# K32W061 register map
Vendor: nxp.com; File version: 1.0
CPU: CM4 r0p1, little endian, MPU, no FPU, VTOR, 3 interrupt priority bits
Registers are 32-bit, read-write, reset 0x0 unless marked. A register's access mark holds for its fields unless they carry their own. Offsets are from the block's base; [hi:lo] are bit positions; {n}, {i} and the like mark numbered series.

## I2C0 — This is the description of component i2c It is an Inter IC with APB bus interface. More details will follow.
Base 0x40003000; alternate view of FLEXCOMM2
Same registers: I2C1 0x40004000 (alternate view of FLEXCOMM3), I2C2 0x40005000 (alternate view of FLEXCOMM6)
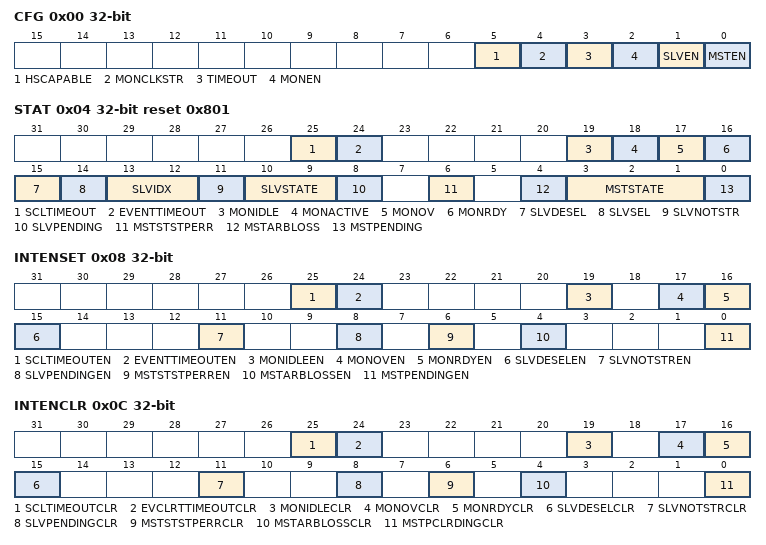
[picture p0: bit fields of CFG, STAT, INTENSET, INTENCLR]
0x00 CFG — Configuration for shared functions.
  [5] HSCAPABLE — High-speed mode Capable enable. Since High Speed mode alters the way I2C pins drive and filter, as well as the timing for certain I2C signalling, enabling High-speed mode applies to all functions: master, slave, and monitor.
  [4] MONCLKSTR — Monitor function Clock Stretching.
  [3] TIMEOUT — I2C bus Time-out Enable. When disabled, the time-out function is internally reset.
  [2] MONEN — Monitor Enable. When disabled, configurations settings for the Monitor function are not changed, but the Monitor function is internally reset.
  [1] SLVEN — Slave Enable. When disabled, configurations settings for the Slave function are not changed, but the Slave function is internally reset.
  [0] MSTEN — Master Enable. When disabled, configurations settings for the Master function are not changed, but the Master function is internally reset.
0x04 STAT reset 0x801 — Status register for Master, Slave and Monitor functions.
  [25] SCLTIMEOUT — SCL Time-out Interrupt flag. Indicates when SCL has remained low longer than the time specific by the TIMEOUT register. The flag is cleared by writing a 1 to this bit. 0: No time-out. SCL low time has not caused a time-out. 1: Time-out. SCL low time has not caused a time-out.
  [24] EVENTTIMEOUT — Event Time-out Interrupt flag. Indicates when the time between events has been longer than the time specified by the TIMEOUT register. Events include Start, Stop, and clock edges. The flag is cleared by writing a 1 to this bit. No time-out is created when the I2C-bus is idle. 0: No time-out. I2C bus events have not casued a time-out. 1: Event time-out. The time between I2C bus events has been longer than the time specified by the TIMEOUT register.
  [19] MONIDLE — Monitor Idle flag. This flag is set when the Monitor function sees the I2C bus change from active to inactive. This can be used by software to decide when to process data accumulated by the Monitor function. This flag will cause an interrupt when set if enabled via the INTENSET register. The flag can be cleared by writing a 1 to this bit. 0: Not idle. The I2C bus is not idle, or this flag has been cleared by software. 1: Idle. The I2C bus has gone idle at least once since the last time this flag was cleared by software.
  [18] MONACTIVE ro — Monitor Active flag. Indicates when the Monitor function considers the I2C bus to be active. Active is defined here as when some Master is on the bus: a bus Start has occurred more recently than a bus Stop. 0: Inactive. The Monitor function considers the I2C bus to be inactive. 1: Active. The Monitor function considers the I2C bus to be active.
  [17] MONOV — Monitor Overflow flag. 0: No overrun. Monitor data has not overrun 1: Overrun. A monitor data overrun has occurred. This can only happen when Monitor clock stretching is not enabled via the MOCCLKSTR bit in the CFG register. Writing 1 to this bit clears the flag.
  [16] MONRDY ro — Monitor Ready. This flag is cleared when the MONRXDAT register is read. 0: No data. The Monitor function does not currently have data available. 1: Data waiting. The Monitor function has data waiting to be read.
  [15] SLVDESEL — Slave Deselected flag. This flag will cause an interrupt when set if enabled via INTENSET. This flag can be cleared by writing a 1 to this bit. 0: Not deselected. The slave function has not become deslected. This does not mean that it is currently selected. That information can be found in the SLVSEL flag. 1: Deselected. The slave function has become deselected. This is specifically caused by the SLVSEL flag changing from 1 to 0. See the description of SLVSEL for details on when that event occurs.
  [14] SLVSEL — Slave selected flag. SLVSEL is set after an address match when software tells the Slave function to acknowledge the address, or when the address has been automatically acknowledged. It is cleared when another address cycle presents an address that does not match an enabled address on the Slave function, when slave software decides to NACK a matched address, when there is a Stop detected on the bus, when the master NACKs slave data, and in some combinations of Automatic Operation. SLVSEL is not cleared if software NACKs data. 0: Not selected. The slave function is not currently selected. 1: Selected. The slave function is currently selected.
  [13:12] SLVIDX ro — Slave address match Index. This field is valid when the I2C slave function has been selected by receiving an address that matches one of the slave addresses defined by any enabled slave address registers, and provides an identification of the address that was matched. It is possible that more than one address could be matched, but only one match can be reported here. 0: Address 0. Slave address 0 was matched. 1: Address 1. Slave address 1 was matched. 2: Address 2. Slave address 2 was matched. 3: Address 3. Slave address 3 was matched.
  [11] SLVNOTSTR ro — Slave Not Stretching. Indicates when the slave function is stretching the I2C clock. This is needed in order to gracefully invoke Deep Sleep or Power-down modes during slave operation. This read-only flag reflects the slave function status in real time. 0: stretching. The slave function is currently stretching the I2C bus clock. Deep-sleep mode can not be entered at this time. 1. Not stretching. The slave function is not currently stretching the I2C bus clock. Deep-sleep mode could be entered at this time.
  [10:9] SLVSTATE ro — Slave State code. Each value of this field indicates a specific required service for the Slave function. All other values are reserved. See Table 393 for state values and actions. Remark: note that the occurrence of some states and how they are handled are affected by DMA mode and Automatic Operation modes. Slave state codes are: 0: Slave address. Address plus R/W received. At least one of the four slave addresses has been matched by hardware. 1: Slave receive. Received data is available (Slave Receiver mode). 2: Slave transmit. Data can be transmitted (Slave transmitter mode).
  [8] SLVPENDING ro — Slave Pending. Indicates that the Slave function is waiting to continue communication on the I2C-bus and needs software service. This flag will cause an interrupt when set if enabled via INTENSET. The SLVPENDING flag is not set when the DMA is handling an event (if the SLVDMA bit in the SLVCTL register is set). The SLVPENDING flag is read-only and is automatically cleared when a 1 is written to the SLVCONTINUE bit in the SLVCTL register. The point in time when SlvPending is set depends on whether the I2C interface is in HSCAPABLE mode. When the I2C interface is configured to be HSCAPABLE, HS master codes are detected automatically. Due to the requirements of the HS I2C specification, slave addresses must also be detected automatically, since the address must be acknowledged before the clock can be stretched. 0: In progress. The slave function does not currently need service. 1: Pending. The Slave function needs service. Information on what is needed can be found in the adjacent SLVSTATE field.
  [6] MSTSTSTPERR — Master Start/Stop Error flag. This flag can be cleared by software writing a 1 to this bit. It is also cleared automatically a 1 is written to MSTCONTINUE. 0: No start/stop Error has occurred. 1: The master function has experienced a Start/Stop Error. A Start or Stop was detected at a time when it is not allowed by the I2C specification. The Master interface has stopped driving the bus and gone to an idle state, no action is required. A request for a Start could be made, or software could attempt to insure that thet bus has not stalled.
  [4] MSTARBLOSS — Master Arbitration Loss flag. This flag can be cleared by software writing a 1 to this bit. It is also cleared automatically a 1 is written to MSTCONTINUE. 0: No Arbitration Loss has occurred. 1: Arbitration Loss. The mater function has experienced an Arbitration Loss. At this point, the Master function has already stopped driving the bus and gone to an idle state. Software can respond by doing nothing, or by sending a Start in order to attempt to gain control of the bus when it next becomes idle.
  [3:1] MSTSTATE ro — Master State code. The master state code reflects the master state when the MSTPENDING bit is set, that is the master is pending or in the idle state. Each value of this field indicates a specific required service for the Master function. All other values are reserved. 0: Idle. The Master function is available to be used for a new transaction. 1: Receive ready. Received data available (Master Receiver mode). Address plus Read was previously sent and Acknowledged by slave. 2: Transmit ready. Data can be transmitted (Master Transmitter mode). Address plus Write was previously sent and Acknowledged by slave. 3: NACK address. Slave NACKed address. 4: NACK data. Slave NACKed transmitted data.
  [0] MSTPENDING ro — Master Pending. Indicates that the Master is waiting to continue communication on the I2C-bus (pending) or is idle. When the master is pending, the MSTSTATE bits indicate what type of software service if any the master expects. This flag will cause an interrupt when set if, enabled via the INTENSET register. The MSTPENDING flag is not set when the DMA is handling an event (if the MSTDMA bit in the MSTCTL register is set). If the master is in the idle state, and no communication is needed, mask this interrupt. 0: In progress. Communication is in progress and the Master function is busy and cannot currently accept a command. 1: Pending. The Master function needs software service or is in the idle state. If the master is not in the idle state, it is waiting to receive or transmit data or the NACK bit.
0x08 INTENSET — Interrupt Enable Set and read register.
  [25] SCLTIMEOUTEN — SCL time-out interrupt Enable. 0: interrupt is disabled. 1: interrupt is enabled.
  [24] EVENTTIMEOUTEN — Event time-out interrupt Enable. 0: interrupt is disabled. 1: interrupt is enabled.
  [19] MONIDLEEN — Monitor Idle interrupt Enable. 0: interrupt is disabled. 1: interrupt is enabled.
  [17] MONOVEN — Monitor Overrun interrupt Enable. 0: interrupt is disabled. 1: interrupt is enabled.
  [16] MONRDYEN — Monitor data Ready interrupt Enable. 0: interrupt is disabled. 1: interrupt is enabled.
  [15] SLVDESELEN — Slave Deselect interrupt Enable. 0: interrupt is disabled. 1: interrupt is enabled.
  [11] SLVNOTSTREN — Slave Not Stretching interrupt Enable. 0: interrupt is disabled. 1: interrupt is enabled.
  [8] SLVPENDINGEN — Slave Pending interrupt Enable. 0: interrupt is disabled. 1: interrupt is enabled.
  [6] MSTSTSTPERREN — Master Start/Stop Error interrupt Enable. 0: interrupt is disabled. 1: interrupt is enabled.
  [4] MSTARBLOSSEN — Master Arbitration Loss interrupt Enable. 0: interrupt is disabled. 1: interrupt is enabled.
  [0] MSTPENDINGEN — Master Pending interrupt Enable. 0: interrupt is disabled. 1: interrupt is enabled.
0x0C INTENCLR reset not defined — Interrupt Enable Clear register. Writing a 1 to this bit clears the corresponding bit in the INTENSET register, disabling that interrupt. This is a Write-only register.
  [25] SCLTIMEOUTCLR wo — SCL time-out interrupt clear.
  [24] EVCLRTTIMEOUTCLR wo — Event time-out interrupt clear.
  [19] MONIDLECLR wo — Monitor Idle interrupt clear.
  [17] MONOVCLR wo — Monitor Overrun interrupt clear.
  [16] MONRDYCLR wo — Monitor data Ready interrupt clear.
  [15] SLVDESELCLR wo — Slave Deselect interrupt clear.
  [11] SLVNOTSTRCLR wo — Slave Not Stretching interrupt clear.
  [8] SLVPENDINGCLR wo — Slave Pending interrupt clear.
  [6] MSTSTSTPERRCLR wo — Master Start/Stop Error interrupt clear.
  [4] MSTARBLOSSCLR wo — Master Arbitration Loss interrupt clear.
  [0] MSTPCLRDINGCLR wo — Master Pending interrupt clear.
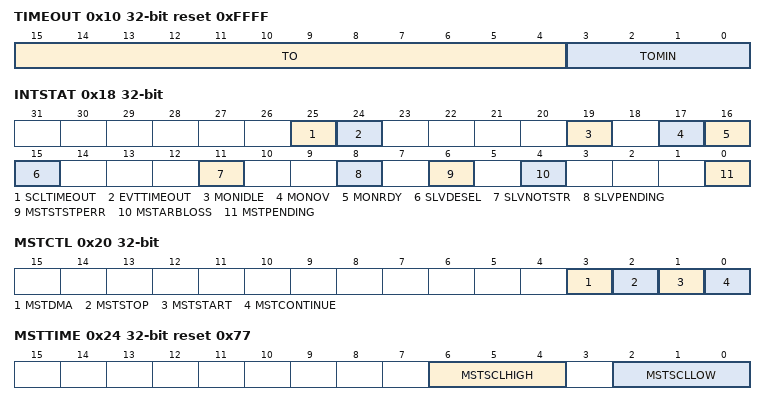
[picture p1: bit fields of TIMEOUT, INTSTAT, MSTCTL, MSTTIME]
0x10 TIMEOUT reset 0xFFFF — Time-out value register.
  [15:4] TO — Time-out time value. Specifies the time-out interval value in increments of 16 I2C function clocks, as defined by the CLKDIV register. To change this value while I2C is in operation, disable all time-outs, write a new value to TIMEOUT, then re-enable time-outs. 0x000: A time-out will occur after 16 counts of the I2C function clock. 0x001: A time-out will occur after 32 counts of the I2C function clock. ... 0xFFF: A time-out will occur after 65,536 counts of the I2C function clock.
  [3:0] TOMIN — Time-out time value, bottom four bits. These are hard-wired to 0xF. This gives a minimum time-out of 16 I2C function clocks and also a time-out resolution of 16 I2C function clocks.
0x14 CLKDIV — Clock pre-divider for the entire I2C interface. This determines what time increments are used for the MSTTIME register and controls some timing of the Slave function.
  [15:0] DIVVAL — This field controls how the I2C clock (FCLK) is used by the I2C functions that need an internal clock in order to operate. I2C block should be configured for 8MHz clock, this will limit SCL master clock range from 444kHz to 2MHz. 0x0000 = FCLK is used directly by the I2C. 0x0001 = FCLK is divided by 2 before use. 0x0002 = FCLK is divided by 3 before use. ... 0xFFFF = FCLK is divided by 65,536 before use.
0x18 INTSTAT ro — Interrupt Status register for Master, Slave and Monitor functions.
  [25] SCLTIMEOUT — SCL time-out interrupt.
  [24] EVTTIMEOUT — Event time-out interrupt.
  [19] MONIDLE — Monitor Idle interrupt.
  [17] MONOV — Monitor Overrun interrupt.
  [16] MONRDY — Monitor data Ready interrupt.
  [15] SLVDESEL — Slave Deselect interrupt.
  [11] SLVNOTSTR — Slave Not Stretching interrupt.
  [8] SLVPENDING — Slave Pending interrupt.
  [6] MSTSTSTPERR — Master Start/Stop Error interrupt.
  [4] MSTARBLOSS — Master Arbitration Loss interrupt.
  [0] MSTPENDING — Master Pending interrupt.
0x20 MSTCTL — Master control register.
  [3] MSTDMA — Master DMA enable. Data operations of the I2C can be performed with DMA. Protocol type operations such as Start, address, Stop, and address match must always be done with software, typically via an interrupt. Address acknowledgement must also be done by software except when the I2C is configured to be HSCAPABLE (and address acknowledgement is handled entirely by hardware) or when Automatic Operation is enabled. When a DMA data transfer is complete, MSTDMA must be cleared prior to beginning the next operation, typically a Start or Stop.This bit is read/write. 0: Disable. No DMA requests are generated for master operation. 1: Enable. A DMA request is generated for I2C master data operations. When this I2C master is generating Acknowledge bits in Master Receiver mode, the acknowledge is generated automatically.
  [2] MSTSTOP — Master Stop control. This bit is write-only. 0: No effect. 1. Stop. A stop will be generated on the I2C bus at the next allowed time, preceded by a NACK to the slave if the master is receiving data from the salve (Master Receiver mode).
  [1] MSTSTART — Master Start control. This bit is write-only. 0: No effect. 1. Start. A start will be generated on the I2C bus at the next allowed time.
  [0] MSTCONTINUE — Master Continue. This bit is write-only. 0: No effect. 1: Continue. Informs the Master function to continue to the next operation. This must be done after writing transmit data, reading received data, or other housekeeping related to the next bus operation.
0x24 MSTTIME reset 0x77 — Master timing configuration.
  [6:4] MSTSCLHIGH — Master SCL High time. Specifies the minimum high time that will be asserted by this master on SCL. Other masters in a multi-master system could shorten this time. This corresponds to the parameter tHIGH in the I2C bus specification. I2C bus specification parameters tSU;STO and tHD;STA have the same values and are also controlled by MSTSCLHIGH.
  [2:0] MSTSCLLOW — Master SCL Low time. Specifies the minimum low time that will be asserted by this master on SCL. Other devices on the bus (masters or slaves) could lengthen this time. This corresponds to the parameter tLOW in the I2C bus specification. I2C bus specification parameters tBUF and tSU;STA have the same values and are also controlled by MSTSCLLOW. The minimum SCL low time is (MSTSCLLOW + 2) clocks of the I2C clock pre-divider.
0x28 MSTDAT — Combined Master receiver and transmitter data register.
  [7:0] DATA — Master function data register. Read: read the most recently received data for the Master function. Write: transmit data using the Master function.
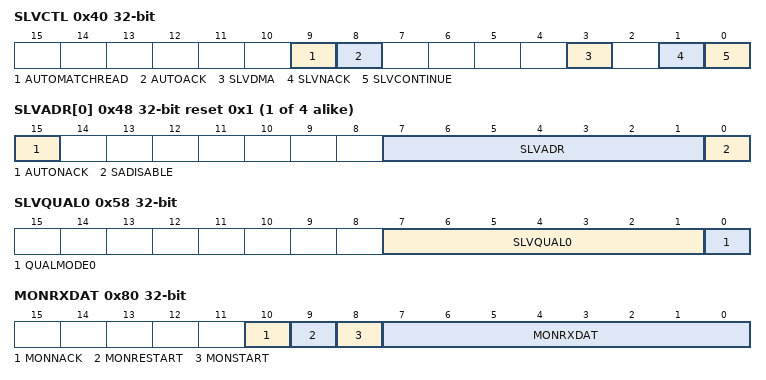
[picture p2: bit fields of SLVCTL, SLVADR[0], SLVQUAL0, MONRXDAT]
0x40 SLVCTL — Slave control register.
  [9] AUTOMATCHREAD — When AUTOACK is set, this bit controls whether it matches a read or write request on the next header with an address matching SLVADR0. Since DMA needs to be configured to match the transfer direction, the direction needs to be specified. This bit allows a direction to be chosen for the next operation. 0: The expected next operation in Automatic Mode is an I2C write. 1: The expected next operation in Automatic Mode is an I2C read.
  [8] AUTOACK — Automatic Acknowledge.When this bit is set, it will cause an I2C header which matches SLVADR0 and the direction set by AUTOMATCHREAD to be ACKed immediately; this is used with DMA to allow processing of the data without intervention. If this bit is clear and a header matches SLVADR0, the behavior is controlled by AUTONACK in the SLVADR0 register: allowing NACK or interrupt. 0: Normal, non-automatic operation. If AUTONACK = 0, an SlvPending interrupt is generated when a matching address is received. If AUTONACK-1, receiver addresses are NACKed (ignored). 1: A header with matching SLVADR0 and matching direction as set by AUTOMATCHREAD will be ACKed immediately, allowing the master to move on to the data bytes. If the address matches SLVADR0, but the direction does not match AUTOMATCHREAD, the behaviour will depend on the AUTONACK bit in the SLVADR0 register: if AUTONACK is set, then it will be Nacked; else if AUTONACK is cl;ear, then a SlvPending interrupt is geernated.
  [3] SLVDMA — Slave DMA enable. 0: Slave DMA enable. 1: Enabled. DMA requests are issued for I2C slave data transmission and reception.
  [1] SLVNACK — Slave NACK. 0: No effect. 1: NACK. Causes the Slave function to NACK the master when the slave is receiving data from the master (Slave Receiver mode).
  [0] SLVCONTINUE — Slave Continue. 0: no effect 1: Continue. Informs the Slave function to continue to the next operation, by clearing the SLVPENDING flag in the STAT register. This must be done after writing transmit data, reading recevied data, or any other housekeeping related to the next bus operation. Automatic Operation has different requirements. SLVCONTINUE should not be set unless SLVPENDING=1.
0x44 SLVDAT — Combined Slave receiver and transmitter data register.
  [7:0] DATA — Slave function data register. Read: read the most recently received data for the Slave function. Write: transmit data using the Slave function.
{0x48+4i} SLVADR[{i}] (i=0..3) reset 0x1 — Slave address 0.
  [15] AUTONACK — Automatic NACK operation. Used in conjunction with AUTOACK and AUTOMATCHREAD, allows software to ignore I2C traffic while handling previous I2C data or other operations. 0: Normal operation, matching I2C addresses are not ignored. 1: Automatic-only mode. If AUTOACK is not set, all incoming I2C addresses are ignored.
  [7:1] SLVADR — Slave Address. Seven bit slave address that is compared to received addresses if enabled. The compare can be affected by the setting of the SLVQUAL0 register.
  [0] SADISABLE — Slave Address 0 Disable. 0: Slave Address 0 is enabled. 1: Slave Address 0 is ignored.
0x58 SLVQUAL0 — Slave Qualification for address 0.
  [7:1] SLVQUAL0 — Slave address Qualifier for address 0. A value of 0 causes the address in SLVADR0 to be used as-is, assuming that it is enabled. If QUALMODE0 = 0, any bit in this field which is set to 1 will cause an automatic match of the corresponding bit of the received address when it is compared to the SLVADR0 register. If QUALMODE0 = 1, an address range is matched for address 0. This range extends from the value defined by SLVADR0 to the address defined by SLVQUAL0 (address matches when SLVADR0[7:1] received address SLVQUAL0[7:1]).
  [0] QUALMODE0 — Qualify mode for slave address 0. 0: Mask. The SLVQUAL0 field is used as a logical mask for matching address 0. 1: Extend. The SLVQAL0 field is used to extend address 0 matching in a range of addresses.
0x80 MONRXDAT ro — Monitor receiver data register.
  [10] MONNACK — Monitor Received NACK. 0: Acknowledged. The data currently being provided by the Monitor function was acknowledged by at least one master or slave recevier. 1: Not Acknowledged. The data currently being provided by the Monitor function was not acknowledged by any receiver.
  [9] MONRESTART — Monitor Received Repeated Start. 0: No repeated start detected. The Monitor function has not detected a Repeated Start event on the I2C bus. 1: Repeate start detected. The Monitor function has detected a Repeated Start event on the I2C bus.
  [8] MONSTART — Monitor Received Start. 0: No start detected. The monitor function has not detected a Start event on the I2C bus. 1: Start detected. The Monitor function has detected a Start event on the I2C bus.
  [7:0] MONRXDAT — Monitor function Receiver Data. This reflects every data byte that passes on the I2C pins.
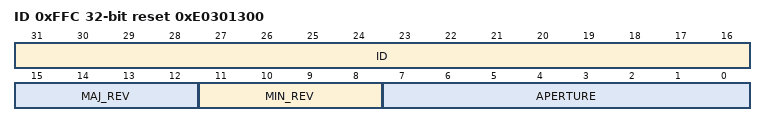
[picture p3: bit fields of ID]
0xFFC ID ro reset 0xE0301300 — I2C Module Identifier
  [31:16] ID — Identifier. This is the unique identifier of the module
  [15:12] MAJ_REV — Major revision i.e. there may be software incompatability between major revisions.
  [11:8] MIN_REV — Minor revision i.e. with no software consequences
  [7:0] APERTURE — Aperture i.e. number minus 1 of consecutive packets 4 Kbytes reserved for this IP
